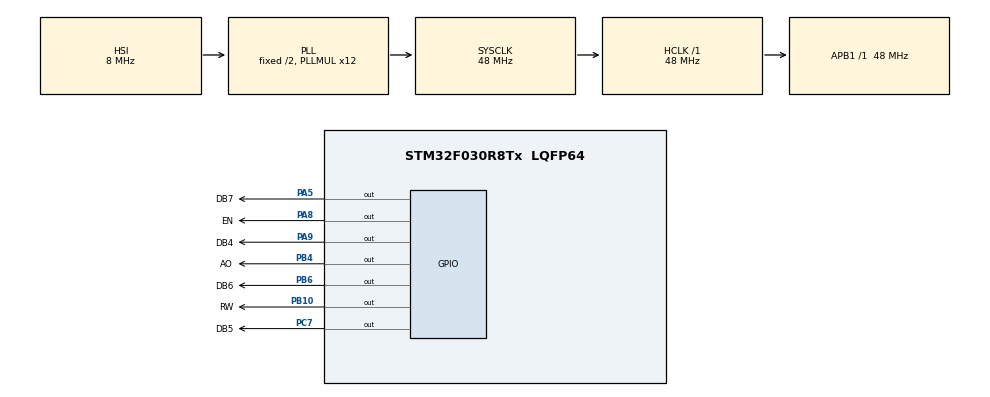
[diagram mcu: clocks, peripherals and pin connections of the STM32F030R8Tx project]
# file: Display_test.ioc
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Mcu.Family=STM32F0
Mcu.Name=STM32F030R8Tx
Mcu.Package=LQFP64
PA5.GPIO_Label=DB7
PA5.Signal=GPIO_Output
PA8.GPIO_Label=EN
PA8.Signal=GPIO_Output
PA9.GPIO_Label=DB4
PA9.Signal=GPIO_Output
PB10.GPIO_Label=RW
PB10.Signal=GPIO_Output
PB4.GPIO_Label=AO
PB4.Signal=GPIO_Output
PB6.GPIO_Label=DB6
PB6.Signal=GPIO_Output
PC7.GPIO_Label=DB5
PC7.Signal=GPIO_Output
ProjectManager.HeapSize=0x200
ProjectManager.StackSize=0x400
ProjectManager.TargetToolchain=STM32CubeIDE
RCC.AHBFreq_Value=48000000
RCC.APB1Freq_Value=48000000
RCC.APB1TimFreq_Value=48000000
RCC.HCLKFreq_Value=48000000
RCC.PLLMUL=RCC_PLL_MUL12
RCC.SYSCLKFreq_VALUE=48000000
RCC.SYSCLKSource=RCC_SYSCLKSOURCE_PLLCLK
TIM3.Period=0
TIM3.Prescaler=47
VP_TIM3_VS_ClockSourceINT.Mode=Internal
board=custom

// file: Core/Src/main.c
/* USER CODE BEGIN Header */
/**
  ******************************************************************************
  * @file           : main.c
  * @brief          : Main program body
  ******************************************************************************
  * @attention
  *
  * Copyright (c) 2023 STMicroelectronics.
  * All rights reserved.
  *
  * This software is licensed under terms that can be found in the LICENSE file
  * in the root directory of this software component.
  * If no LICENSE file comes with this software, it is provided AS-IS.
  *
  ******************************************************************************
  */
/* USER CODE END Header */
#include "main.h"

/* USER CODE BEGIN Includes */
#include "hd44780.h"
/* USER CODE END Includes */

TIM_HandleTypeDef htim3;

void SystemClock_Config(void);
static void MX_GPIO_Init(void);
static void MX_TIM3_Init(void);

int main(void)
{

  /* MCU Configuration--------------------------------------------------------*/

  /* Reset of all peripherals, Initializes the Flash interface and the Systick. */
  HAL_Init();

  /* Configure the system clock */
  SystemClock_Config();

  /* Initialize all configured peripherals */
  MX_GPIO_Init();
  MX_TIM3_Init();
  /* USER CODE BEGIN 2 */
  //lcd_init();
  HAL_Delay(40);
  lcd_send(0x20,COMMAND);
  lcd_clear();
  HAL_Delay(100);
  lcd_set_xyi(1, 1);
  HAL_Delay(10);
  //lcd_out("Привет");
  lcd_send(0x41, DATA);
  /* USER CODE END 2 */

  /* Infinite loop */
  while (1)
  {

  }
}

void SystemClock_Config(void)
{
  RCC_OscInitTypeDef RCC_OscInitStruct = {0};
  RCC_ClkInitTypeDef RCC_ClkInitStruct = {0};

  /** Initializes the RCC Oscillators according to the specified parameters
  * in the RCC_OscInitTypeDef structure.
  */
  RCC_OscInitStruct.OscillatorType = RCC_OSCILLATORTYPE_HSI;
  RCC_OscInitStruct.HSIState = RCC_HSI_ON;
  RCC_OscInitStruct.HSICalibrationValue = RCC_HSICALIBRATION_DEFAULT;
  RCC_OscInitStruct.PLL.PLLState = RCC_PLL_ON;
  RCC_OscInitStruct.PLL.PLLSource = RCC_PLLSOURCE_HSI;
  RCC_OscInitStruct.PLL.PLLMUL = RCC_PLL_MUL12;
  RCC_OscInitStruct.PLL.PREDIV = RCC_PREDIV_DIV1;
  if (HAL_RCC_OscConfig(&RCC_OscInitStruct) != HAL_OK)
  {
    Error_Handler();
  }

  /** Initializes the CPU, AHB and APB buses clocks
  */
  RCC_ClkInitStruct.ClockType = RCC_CLOCKTYPE_HCLK|RCC_CLOCKTYPE_SYSCLK
                              |RCC_CLOCKTYPE_PCLK1;
  RCC_ClkInitStruct.SYSCLKSource = RCC_SYSCLKSOURCE_PLLCLK;
  RCC_ClkInitStruct.AHBCLKDivider = RCC_SYSCLK_DIV1;
  RCC_ClkInitStruct.APB1CLKDivider = RCC_HCLK_DIV1;

  if (HAL_RCC_ClockConfig(&RCC_ClkInitStruct, FLASH_LATENCY_1) != HAL_OK)
  {
    Error_Handler();
  }
}

static void MX_TIM3_Init(void)
{

  TIM_ClockConfigTypeDef sClockSourceConfig = {0};
  TIM_MasterConfigTypeDef sMasterConfig = {0};

  htim3.Instance = TIM3;
  htim3.Init.Prescaler = 47;
  htim3.Init.CounterMode = TIM_COUNTERMODE_UP;
  htim3.Init.Period = 0;
  htim3.Init.ClockDivision = TIM_CLOCKDIVISION_DIV1;
  htim3.Init.AutoReloadPreload = TIM_AUTORELOAD_PRELOAD_DISABLE;
  if (HAL_TIM_Base_Init(&htim3) != HAL_OK)
  {
    Error_Handler();
  }
  sClockSourceConfig.ClockSource = TIM_CLOCKSOURCE_INTERNAL;
  if (HAL_TIM_ConfigClockSource(&htim3, &sClockSourceConfig) != HAL_OK)
  {
    Error_Handler();
  }
  sMasterConfig.MasterOutputTrigger = TIM_TRGO_RESET;
  sMasterConfig.MasterSlaveMode = TIM_MASTERSLAVEMODE_DISABLE;
  if (HAL_TIMEx_MasterConfigSynchronization(&htim3, &sMasterConfig) != HAL_OK)
  {
    Error_Handler();
  }

}

static void MX_GPIO_Init(void)
{
  GPIO_InitTypeDef GPIO_InitStruct = {0};

  /* GPIO Ports Clock Enable */
  __HAL_RCC_GPIOA_CLK_ENABLE();
  __HAL_RCC_GPIOB_CLK_ENABLE();
  __HAL_RCC_GPIOC_CLK_ENABLE();

  /*Configure GPIO pin Output Level */
  HAL_GPIO_WritePin(GPIOA, DB7_Pin|EN_Pin|DB4_Pin, GPIO_PIN_RESET);

  /*Configure GPIO pin Output Level */
  HAL_GPIO_WritePin(GPIOB, RW_Pin|AO_Pin|DB6_Pin, GPIO_PIN_RESET);

  /*Configure GPIO pin Output Level */
  HAL_GPIO_WritePin(DB5_GPIO_Port, DB5_Pin, GPIO_PIN_RESET);

  /*Configure GPIO pins : DB7_Pin EN_Pin DB4_Pin */
  GPIO_InitStruct.Pin = DB7_Pin|EN_Pin|DB4_Pin;
  GPIO_InitStruct.Mode = GPIO_MODE_OUTPUT_PP;
  GPIO_InitStruct.Pull = GPIO_NOPULL;
  GPIO_InitStruct.Speed = GPIO_SPEED_FREQ_LOW;
  HAL_GPIO_Init(GPIOA, &GPIO_InitStruct);

  /*Configure GPIO pins : RW_Pin AO_Pin DB6_Pin */
  GPIO_InitStruct.Pin = RW_Pin|AO_Pin|DB6_Pin;
  GPIO_InitStruct.Mode = GPIO_MODE_OUTPUT_PP;
  GPIO_InitStruct.Pull = GPIO_NOPULL;
  GPIO_InitStruct.Speed = GPIO_SPEED_FREQ_LOW;
  HAL_GPIO_Init(GPIOB, &GPIO_InitStruct);

  /*Configure GPIO pin : DB5_Pin */
  GPIO_InitStruct.Pin = DB5_Pin;
  GPIO_InitStruct.Mode = GPIO_MODE_OUTPUT_PP;
  GPIO_InitStruct.Pull = GPIO_NOPULL;
  GPIO_InitStruct.Speed = GPIO_SPEED_FREQ_LOW;
  HAL_GPIO_Init(DB5_GPIO_Port, &GPIO_InitStruct);

}

void Error_Handler(void)
{
  __disable_irq();
  while (1)
  {
  }
}
